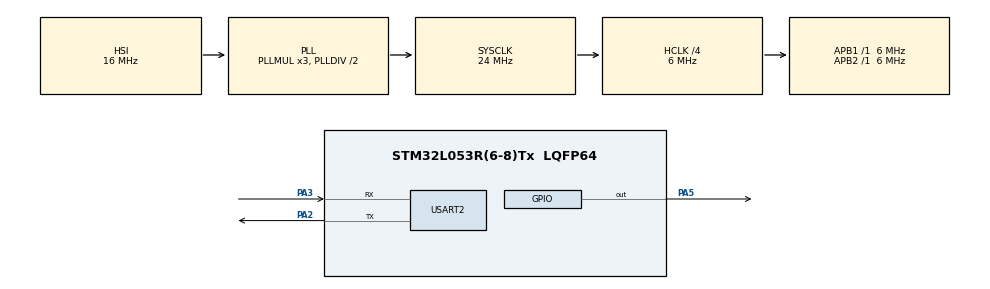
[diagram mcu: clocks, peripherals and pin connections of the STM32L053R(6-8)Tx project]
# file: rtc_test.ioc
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Mcu.Family=STM32L0
Mcu.Name=STM32L053R(6-8)Tx
Mcu.Package=LQFP64
NVIC.RTC_IRQn=true\:0\:0\:false\:false\:true
PA2.Mode=Asynchronous
PA2.Signal=USART2_TX
PA3.Mode=Asynchronous
PA3.Signal=USART2_RX
PA5.Signal=GPIO_Output
PC14-OSC32_IN.Mode=LSE-External-Oscillator
PC14-OSC32_IN.Signal=RCC_OSC32_IN
PC15-OSC32_OUT.Mode=LSE-External-Oscillator
PC15-OSC32_OUT.Signal=RCC_OSC32_OUT
ProjectManager.HeapSize=0x200
ProjectManager.StackSize=0x400
ProjectManager.TargetToolchain=MDK-ARM V5
RCC.AHBCLKDivider=RCC_SYSCLK_DIV4
RCC.AHBFreq_Value=6000000
RCC.APB1Freq_Value=6000000
RCC.APB1TimFreq_Value=6000000
RCC.APB2Freq_Value=6000000
RCC.APB2TimFreq_Value=6000000
RCC.HCLKFreq_Value=6000000
RCC.HSE_VALUE=8000000
RCC.HSI16_VALUE=16000000
RCC.HSI48_VALUE=48000000
RCC.HSI_VALUE=16000000
RCC.MSI_VALUE=2097000
RCC.RTCClockSelection=RCC_RTCCLKSOURCE_LSE
RCC.RTCClockSelectionVirtual=RCC_RTCCLKSOURCE_LSE
RCC.SYSCLKFreq_VALUE=24000000
RCC.SYSCLKSource=RCC_SYSCLKSOURCE_PLLCLK
RCC.VCOOutputFreq_Value=48000000
RTC.Alarm-Alarm\ A=RTC_ALARM_A
RTC.AlarmDateWeekDay-Alarm\ A=RTC_WEEKDAY_SUNDAY
RTC.AlarmDateWeekDaySel-Alarm\ A=RTC_ALARMDATEWEEKDAYSEL_WEEKDAY
RTC.AlarmDateWeekDaySel_B-Alarm\ B=RTC_ALARMDATEWEEKDAYSEL_WEEKDAY
RTC.AlarmDateWeekDay_B-Alarm\ B=RTC_WEEKDAY_SATURDAY
RTC.AlarmMaskDateWeekDay-Alarm\ A=RTC_ALARMMASK_DATEWEEKDAY
RTC.AlarmMaskDateWeekDay_B-Alarm\ B=RTC_ALARMMASK_DATEWEEKDAY
RTC.Alarm_B-Alarm\ B=RTC_ALARM_B
RTC.Date=24
RTC.HourFormat=RTC_HOURFORMAT_12
RTC.Hours=5
RTC.Hours_A-Alarm\ A=5
RTC.Hours_B-Alarm\ B=5
RTC.Minutes=43
RTC.Minutes_A-Alarm\ A=43
RTC.Minutes_B-Alarm\ B=44
RTC.Seconds_A-Alarm\ A=30
RTC.TimeFormat=RTC_HOURFORMAT12_PM
RTC.WeekDay=RTC_WEEKDAY_SUNDAY
RTC.Year=17
USART2.VirtualMode-Asynchronous=VM_ASYNC
USART2.WordLength=WORDLENGTH_8B
VP_RTC_VS_RTC_Activate.Mode=RTC_Enabled
VP_RTC_VS_RTC_Alarm_A_Intern.Mode=Alarm A
VP_RTC_VS_RTC_Alarm_B_Intern.Mode=Alarm B
VP_RTC_VS_RTC_Calendar.Mode=RTC_Calendar
board=rtc_test

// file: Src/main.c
/**
  ******************************************************************************
  * File Name          : main.c
  * Description        : Main program body
  ******************************************************************************
  ** This notice applies to any and all portions of this file
  * that are not between comment pairs USER CODE BEGIN and
  * USER CODE END. Other portions of this file, whether
  * inserted by the user or by software development tools
  * are owned by their respective copyright owners.
  *
  * COPYRIGHT(c) 2017 STMicroelectronics
  *
  * Redistribution and use in source and binary forms, with or without modification,
  * are permitted provided that the following conditions are met:
  *   1. Redistributions of source code must retain the above copyright notice,
  *      this list of conditions and the following disclaimer.
  *   2. Redistributions in binary form must reproduce the above copyright notice,
  *      this list of conditions and the following disclaimer in the documentation
  *      and/or other materials provided with the distribution.
  *   3. Neither the name of STMicroelectronics nor the names of its contributors
  *      may be used to endorse or promote products derived from this software
  *      without specific prior written permission.
  *
  * THIS SOFTWARE IS PROVIDED BY THE COPYRIGHT HOLDERS AND CONTRIBUTORS "AS IS"
  * AND ANY EXPRESS OR IMPLIED WARRANTIES, INCLUDING, BUT NOT LIMITED TO, THE
  * IMPLIED WARRANTIES OF MERCHANTABILITY AND FITNESS FOR A PARTICULAR PURPOSE ARE
  * DISCLAIMED. IN NO EVENT SHALL THE COPYRIGHT HOLDER OR CONTRIBUTORS BE LIABLE
  * FOR ANY DIRECT, INDIRECT, INCIDENTAL, SPECIAL, EXEMPLARY, OR CONSEQUENTIAL
  * DAMAGES (INCLUDING, BUT NOT LIMITED TO, PROCUREMENT OF SUBSTITUTE GOODS OR
  * SERVICES; LOSS OF USE, DATA, OR PROFITS; OR BUSINESS INTERRUPTION) HOWEVER
  * CAUSED AND ON ANY THEORY OF LIABILITY, WHETHER IN CONTRACT, STRICT LIABILITY,
  * OR TORT (INCLUDING NEGLIGENCE OR OTHERWISE) ARISING IN ANY WAY OUT OF THE USE
  * OF THIS SOFTWARE, EVEN IF ADVISED OF THE POSSIBILITY OF SUCH DAMAGE.
  *
  ******************************************************************************
  */
#include "main.h"
#include "stm32l0xx_hal.h"

/* USER CODE BEGIN Includes */
void UART2_SendByte(uint8_t data)
{
  while((USART2->ISR&UART_FLAG_TXE)!=UART_FLAG_TXE);//等待发送寄存器为空
  USART2->TDR = data;
}
RTC_DateTypeDef RTC_Date;
RTC_TimeTypeDef RTC_Time;
/* USER CODE END Includes */

RTC_HandleTypeDef hrtc;

UART_HandleTypeDef huart2;

/* USER CODE BEGIN PV */
/* Private variables ---------------------------------------------------------*/
#ifdef __GNUC__
  /* With GCC/RAISONANCE, small printf (option LD Linker->Libraries->Small printf
     set to 'Yes') calls __io_putchar() */
  #define PUTCHAR_PROTOTYPE int __io_putchar(int ch)
#else
  #define PUTCHAR_PROTOTYPE int fputc(int ch, FILE *f)
#endif /* __GNUC__ */

PUTCHAR_PROTOTYPE
{
  /* Place your implementation of fputc here */
  /* e.g. write a character to the USART */
  while((USART2->ISR&UART_FLAG_TXE)!=UART_FLAG_TXE);//等待发送寄存器为空
  UART2_SendByte(ch);
  return ch;
}

/* USER CODE END PV */

void SystemClock_Config(void);
static void MX_GPIO_Init(void);
static void MX_RTC_Init(void);
static void MX_USART2_UART_Init(void);

/* USER CODE BEGIN PFP */
/* Private function prototypes -----------------------------------------------*/

/* USER CODE END PFP */

int main(void)
{

  /* MCU Configuration----------------------------------------------------------*/

  /* Reset of all peripherals, Initializes the Flash interface and the Systick. */
  HAL_Init();

  /* Configure the system clock */
  SystemClock_Config();

  /* Initialize all configured peripherals */
  MX_GPIO_Init();
  MX_RTC_Init();
  MX_USART2_UART_Init();

  /* USER CODE BEGIN 2 */
  printf("uart test\r\n");
  /* USER CODE END 2 */

  /* Infinite loop */
  while (1)
  {

  /* USER CODE BEGIN 3 */
			  HAL_RTC_GetDate(&hrtc, &RTC_Date, FORMAT_BIN);
        HAL_RTC_GetTime(&hrtc, &RTC_Time, FORMAT_BIN);
		    printf("RTC_Date:  20%2d.%2d.%2d  星期%d\r\n", RTC_Date.Year, RTC_Date.Month, RTC_Date.Date, RTC_Date.WeekDay);
        printf("RTC_Time:  %2d:%2d:%2d\r\n", RTC_Time.Hours, RTC_Time.Minutes, RTC_Time.Seconds);
		    HAL_Delay(800);
  }
  /* USER CODE END 3 */

}

/** System Clock Configuration
*/
void SystemClock_Config(void)
{

  RCC_OscInitTypeDef RCC_OscInitStruct;
  RCC_ClkInitTypeDef RCC_ClkInitStruct;
  RCC_PeriphCLKInitTypeDef PeriphClkInit;

    /**Configure the main internal regulator output voltage
    */
  __HAL_PWR_VOLTAGESCALING_CONFIG(PWR_REGULATOR_VOLTAGE_SCALE1);

    /**Configure LSE Drive Capability
    */
  __HAL_RCC_LSEDRIVE_CONFIG(RCC_LSEDRIVE_LOW);

    /**Initializes the CPU, AHB and APB busses clocks
    */
  RCC_OscInitStruct.OscillatorType = RCC_OSCILLATORTYPE_HSI|RCC_OSCILLATORTYPE_LSE;
  RCC_OscInitStruct.LSEState = RCC_LSE_ON;
  RCC_OscInitStruct.HSIState = RCC_HSI_ON;
  RCC_OscInitStruct.HSICalibrationValue = 16;
  RCC_OscInitStruct.PLL.PLLState = RCC_PLL_ON;
  RCC_OscInitStruct.PLL.PLLSource = RCC_PLLSOURCE_HSI;
  RCC_OscInitStruct.PLL.PLLMUL = RCC_PLLMUL_3;
  RCC_OscInitStruct.PLL.PLLDIV = RCC_PLLDIV_2;
  if (HAL_RCC_OscConfig(&RCC_OscInitStruct) != HAL_OK)
  {
    _Error_Handler(__FILE__, __LINE__);
  }

    /**Initializes the CPU, AHB and APB busses clocks
    */
  RCC_ClkInitStruct.ClockType = RCC_CLOCKTYPE_HCLK|RCC_CLOCKTYPE_SYSCLK
                              |RCC_CLOCKTYPE_PCLK1|RCC_CLOCKTYPE_PCLK2;
  RCC_ClkInitStruct.SYSCLKSource = RCC_SYSCLKSOURCE_PLLCLK;
  RCC_ClkInitStruct.AHBCLKDivider = RCC_SYSCLK_DIV4;
  RCC_ClkInitStruct.APB1CLKDivider = RCC_HCLK_DIV1;
  RCC_ClkInitStruct.APB2CLKDivider = RCC_HCLK_DIV1;

  if (HAL_RCC_ClockConfig(&RCC_ClkInitStruct, FLASH_LATENCY_0) != HAL_OK)
  {
    _Error_Handler(__FILE__, __LINE__);
  }

  PeriphClkInit.PeriphClockSelection = RCC_PERIPHCLK_USART2|RCC_PERIPHCLK_RTC;
  PeriphClkInit.Usart2ClockSelection = RCC_USART2CLKSOURCE_PCLK1;
  PeriphClkInit.RTCClockSelection = RCC_RTCCLKSOURCE_LSE;
  if (HAL_RCCEx_PeriphCLKConfig(&PeriphClkInit) != HAL_OK)
  {
    _Error_Handler(__FILE__, __LINE__);
  }

    /**Configure the Systick interrupt time
    */
  HAL_SYSTICK_Config(HAL_RCC_GetHCLKFreq()/1000);

    /**Configure the Systick
    */
  HAL_SYSTICK_CLKSourceConfig(SYSTICK_CLKSOURCE_HCLK);

  /* SysTick_IRQn interrupt configuration */
  HAL_NVIC_SetPriority(SysTick_IRQn, 0, 0);
}

/* RTC init function */
static void MX_RTC_Init(void)
{

  RTC_TimeTypeDef sTime;
  RTC_DateTypeDef sDate;
  RTC_AlarmTypeDef sAlarm;

    /**Initialize RTC Only
    */
  hrtc.Instance = RTC;
  hrtc.Init.HourFormat = RTC_HOURFORMAT_12;
  hrtc.Init.AsynchPrediv = 127;
  hrtc.Init.SynchPrediv = 255;
  hrtc.Init.OutPut = RTC_OUTPUT_DISABLE;
  hrtc.Init.OutPutRemap = RTC_OUTPUT_REMAP_NONE;
  hrtc.Init.OutPutPolarity = RTC_OUTPUT_POLARITY_HIGH;
  hrtc.Init.OutPutType = RTC_OUTPUT_TYPE_OPENDRAIN;
  if (HAL_RTC_Init(&hrtc) != HAL_OK)
  {
    _Error_Handler(__FILE__, __LINE__);
  }

    /**Initialize RTC and set the Time and Date
    */
  if(HAL_RTCEx_BKUPRead(&hrtc, RTC_BKP_DR0) != 0x32F9){
  sTime.Hours = 0x5;
  sTime.Minutes = 0x43;
  sTime.Seconds = 0x0;
  sTime.TimeFormat = RTC_HOURFORMAT12_PM;
  sTime.DayLightSaving = RTC_DAYLIGHTSAVING_NONE;
  sTime.StoreOperation = RTC_STOREOPERATION_RESET;
  if (HAL_RTC_SetTime(&hrtc, &sTime, RTC_FORMAT_BCD) != HAL_OK)
  {
    _Error_Handler(__FILE__, __LINE__);
  }

  sDate.WeekDay = RTC_WEEKDAY_SUNDAY;
  sDate.Month = RTC_MONTH_JANUARY;
  sDate.Date = 0x24;
  sDate.Year = 0x17;

  if (HAL_RTC_SetDate(&hrtc, &sDate, RTC_FORMAT_BCD) != HAL_OK)
  {
    _Error_Handler(__FILE__, __LINE__);
  }

    HAL_RTCEx_BKUPWrite(&hrtc,RTC_BKP_DR0,0x32F9);
  }
    /**Enable the Alarm A
    */
  sAlarm.AlarmTime.Hours = 0x5;
  sAlarm.AlarmTime.Minutes = 0x43;
  sAlarm.AlarmTime.Seconds = 0x20;
  sAlarm.AlarmTime.SubSeconds = 0x0;
  sAlarm.AlarmTime.TimeFormat = RTC_HOURFORMAT12_PM;
  sAlarm.AlarmTime.DayLightSaving = RTC_DAYLIGHTSAVING_NONE;
  sAlarm.AlarmTime.StoreOperation = RTC_STOREOPERATION_RESET;
  sAlarm.AlarmMask = RTC_ALARMMASK_NONE;
  sAlarm.AlarmSubSecondMask = RTC_ALARMSUBSECONDMASK_NONE;
  sAlarm.AlarmDateWeekDaySel = RTC_ALARMDATEWEEKDAYSEL_WEEKDAY;
  sAlarm.AlarmDateWeekDay = RTC_WEEKDAY_SATURDAY;
  sAlarm.Alarm = RTC_ALARM_A;
  if (HAL_RTC_SetAlarm_IT(&hrtc, &sAlarm, RTC_FORMAT_BCD) != HAL_OK)
  {
    _Error_Handler(__FILE__, __LINE__);
  }

    /**Enable the Alarm B
    */
  sAlarm.AlarmTime.Minutes = 0x43;
  sAlarm.AlarmTime.Seconds = 0x40;
  sAlarm.AlarmDateWeekDay = RTC_WEEKDAY_SUNDAY;
  sAlarm.Alarm = RTC_ALARM_B;
  if (HAL_RTC_SetAlarm_IT(&hrtc, &sAlarm, RTC_FORMAT_BCD) != HAL_OK)
  {
    _Error_Handler(__FILE__, __LINE__);
  }

}

/* USART2 init function */
static void MX_USART2_UART_Init(void)
{

  huart2.Instance = USART2;
  huart2.Init.BaudRate = 115200;
  huart2.Init.WordLength = UART_WORDLENGTH_8B;
  huart2.Init.StopBits = UART_STOPBITS_1;
  huart2.Init.Parity = UART_PARITY_NONE;
  huart2.Init.Mode = UART_MODE_TX_RX;
  huart2.Init.HwFlowCtl = UART_HWCONTROL_NONE;
  huart2.Init.OverSampling = UART_OVERSAMPLING_16;
  huart2.Init.OneBitSampling = UART_ONE_BIT_SAMPLE_DISABLE;
  huart2.AdvancedInit.AdvFeatureInit = UART_ADVFEATURE_NO_INIT;
  if (HAL_UART_Init(&huart2) != HAL_OK)
  {
    _Error_Handler(__FILE__, __LINE__);
  }

}

/** Configure pins as
        * Analog
        * Input
        * Output
        * EVENT_OUT
        * EXTI
*/
static void MX_GPIO_Init(void)
{

  GPIO_InitTypeDef GPIO_InitStruct;

  /* GPIO Ports Clock Enable */
  __HAL_RCC_GPIOC_CLK_ENABLE();
  __HAL_RCC_GPIOA_CLK_ENABLE();

  /*Configure GPIO pin Output Level */
  HAL_GPIO_WritePin(GPIOA, GPIO_PIN_5, GPIO_PIN_RESET);

  /*Configure GPIO pin : PA5 */
  GPIO_InitStruct.Pin = GPIO_PIN_5;
  GPIO_InitStruct.Mode = GPIO_MODE_OUTPUT_PP;
  GPIO_InitStruct.Pull = GPIO_NOPULL;
  GPIO_InitStruct.Speed = GPIO_SPEED_FREQ_LOW;
  HAL_GPIO_Init(GPIOA, &GPIO_InitStruct);

}

/* USER CODE BEGIN 4 */

void HAL_RTC_AlarmAEventCallback(RTC_HandleTypeDef *hrtc)
{

 HAL_GPIO_WritePin(GPIOA, GPIO_PIN_5, GPIO_PIN_RESET);

}

void HAL_RTCEx_AlarmBEventCallback(RTC_HandleTypeDef *hrtc)
{

 HAL_GPIO_WritePin(GPIOA, GPIO_PIN_5, GPIO_PIN_SET);

}

/* USER CODE END 4 */

void _Error_Handler(char * file, int line)
{
  while(1)
  {
  }
}

/************************ (C) COPYRIGHT STMicroelectronics *****END OF FILE****/
